# HDSC_HC32L110B4PA register map
Vendor: HDSC Co.Ltd; Series: ARMCM0P; File version: 1.2
CPU: CM0 r0p0, little endian, no MPU, no FPU, 3 interrupt priority bits
Registers are 32-bit, read-write, reset 0x0 unless marked. A register's access mark holds for its fields unless they carry their own. Offsets are from the block's base; [hi:lo] are bit positions; {n}, {i} and the like mark numbered series.

## BGR
Base 0x40002400; alternate view of ADC
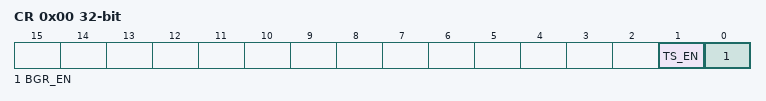
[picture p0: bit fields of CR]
0x00 CR
  [1] TS_EN, [0] BGR_EN

## BT0 — desc BT
Base 0x40000C00
Same registers: BT1 0x40000C20, BT2 0x40000C40
0x00 ARR (reset mask 0xFF)
  [15:0] ARR
0x04 CNT (reset mask 0xFF)
  [15:0] CNT
0x08 CNT32
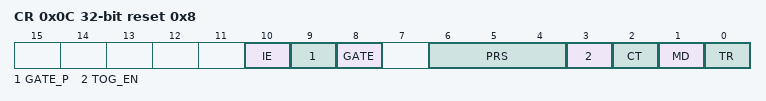
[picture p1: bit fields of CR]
0x0C CR reset 0x8
  [10] IE, [9] GATE_P, [8] GATE, [6:4] PRS, [3] TOG_EN, [2] CT, [1] MD, [0] TR
0x10 IFR ro
  [0] TF
0x14 ICLR wo reset 0x1
  [0] TFC

## CLK_TRIM
Base 0x40001800
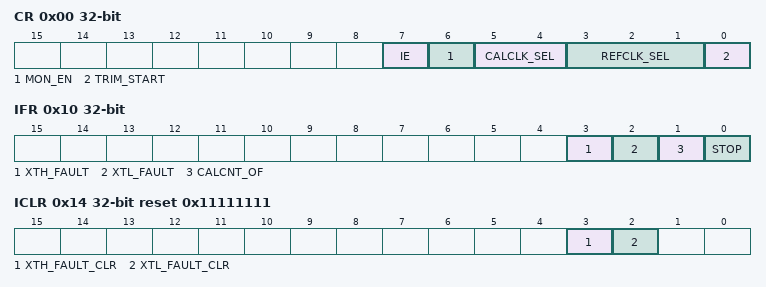
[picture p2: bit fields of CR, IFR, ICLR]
0x00 CR
  [7] IE, [6] MON_EN, [5:4] CALCLK_SEL, [3:1] REFCLK_SEL, [0] TRIM_START
0x04 REFCON
  [31:0] RCNTVAL
0x08 REFCNT ro
0x0C CALCNT ro
0x10 IFR ro
  [3] XTH_FAULT, [2] XTL_FAULT, [1] CALCNT_OF, [0] STOP
0x14 ICLR reset 0x11111111
  [3] XTH_FAULT_CLR, [2] XTL_FAULT_CLR
0x18 CALCON reset 0xFFFFFFFF
  [31:0] CCNTVAL

## CLOCK
Base 0x40002000
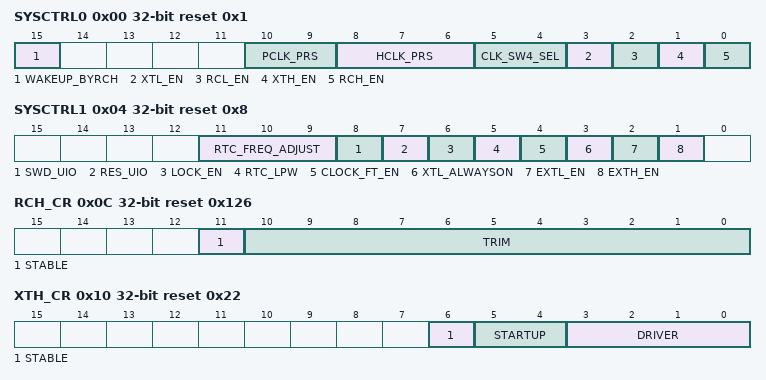
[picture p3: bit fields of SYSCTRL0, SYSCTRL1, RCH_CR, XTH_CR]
0x00 SYSCTRL0 reset 0x1
  [15] WAKEUP_BYRCH, [10:9] PCLK_PRS, [8:6] HCLK_PRS, [5:4] CLK_SW4_SEL, [3] XTL_EN, [2] RCL_EN, [1] XTH_EN, [0] RCH_EN
0x04 SYSCTRL1 reset 0x8
  [11:9] RTC_FREQ_ADJUST, [8] SWD_UIO, [7] RES_UIO, [6] LOCK_EN, [5] RTC_LPW, [4] CLOCK_FT_EN, [3] XTL_ALWAYSON, [2] EXTL_EN, [1] EXTH_EN
0x08 SYSCTRL2
  [15:0] SYSCTRL2
0x0C RCH_CR reset 0x126
  [11] STABLE ro, [10:0] TRIM
0x10 XTH_CR reset 0x22
  [6] STABLE ro, [5:4] STARTUP, [3:0] DRIVER
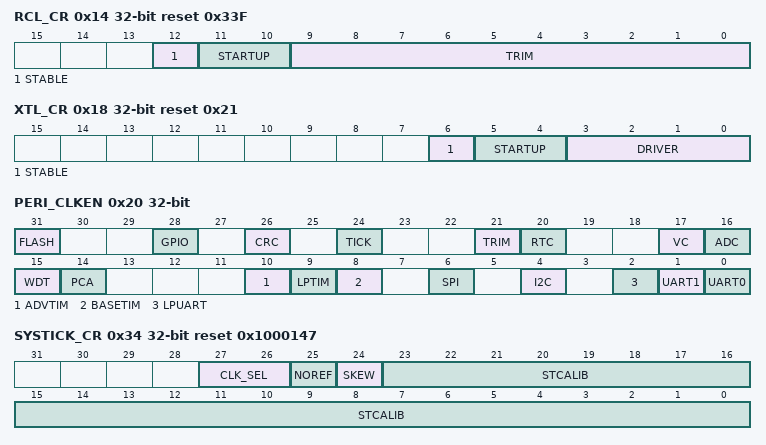
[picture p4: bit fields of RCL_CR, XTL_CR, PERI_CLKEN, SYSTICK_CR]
0x14 RCL_CR reset 0x33F
  [12] STABLE ro, [11:10] STARTUP, [9:0] TRIM
0x18 XTL_CR reset 0x21
  [6] STABLE ro, [5:4] STARTUP, [3:0] DRIVER
0x20 PERI_CLKEN
  [31] FLASH, [28] GPIO, [26] CRC, [24] TICK, [21] TRIM, [20] RTC, [17] VC, [16] ADC, [15] WDT, [14] PCA, [10] ADVTIM, [9] LPTIM, [8] BASETIM, [6] SPI, [4] I2C, [2] LPUART, [1] UART1, [0] UART0
0x34 SYSTICK_CR reset 0x1000147
  [27:26] CLK_SEL, [25] NOREF, [24] SKEW, [23:0] STCALIB
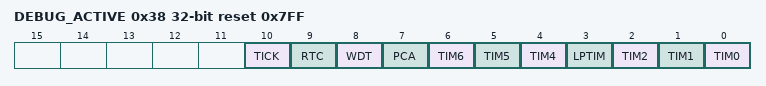
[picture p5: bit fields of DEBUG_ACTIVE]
0x38 DEBUG_ACTIVE reset 0x7FF
  [10] TICK, [9] RTC, [8] WDT, [7] PCA, [6] TIM6, [5] TIM5, [4] TIM4, [3] LPTIM, [2] TIM2, [1] TIM1, [0] TIM0

## CRC
Base 0x40020900
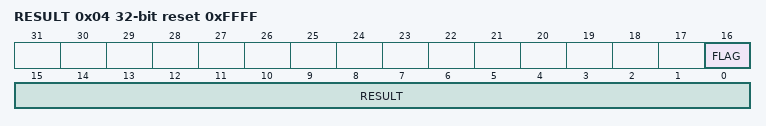
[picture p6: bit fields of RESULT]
0x04 RESULT reset 0xFFFF
  [16] FLAG ro, [15:0] RESULT
0x80 DATA wo

## FLASH
Base 0x40020000
0x00 TNVS reset 0x32
  [8:0] TNVS
0x04 TPGS reset 0x23
  [7:0] TPGS
0x08 TPROG reset 0x27
  [7:0] TPROG
0x0C TSERASE reset 0x18000
  [17:0] TSERASE
0x10 TMERASE reset 0x140000
  [20:0] TMERASE
0x14 TPRCV reset 0x24
  [11:0] TPRCV
0x18 TSRCV reset 0x240
  [11:0] TSRCV
0x1C TMRCV reset 0x1000
  [12:0] TMRCV
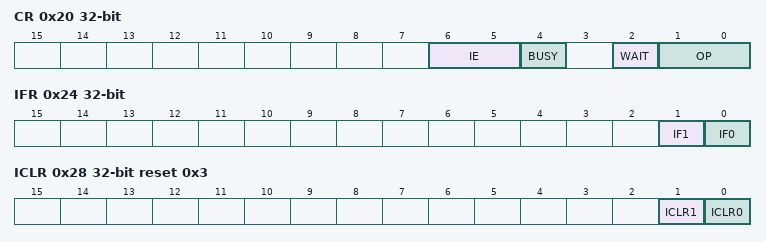
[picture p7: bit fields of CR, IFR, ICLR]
0x20 CR
  [6:5] IE, [4] BUSY ro, [2] WAIT, [1:0] OP
0x24 IFR ro
  [1] IF1, [0] IF0
0x28 ICLR wo reset 0x3
  [1] ICLR1, [0] ICLR0
0x2C BYPASS wo
  [15:0] BYSEQ
0x30 SLOCK
  [15:0] SLOCK

## GPIO
Base 0x40020C00
0x04 P01_SEL
  [2:0] SEL
0x08 P02_SEL
  [2:0] SEL
0x50 P14_SEL
  [2:0] SEL
0x54 P15_SEL
  [2:0] SEL
{0x30+4i} P{i}_SEL (i=23..27)
  [2:0] SEL
0xC4 P31_SEL
  [2:0] SEL
0xD4 P35_SEL
  [2:0] SEL
0xD8 P36_SEL
  [2:0] SEL
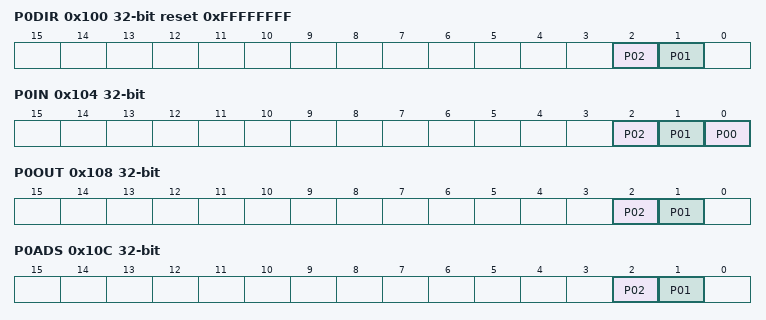
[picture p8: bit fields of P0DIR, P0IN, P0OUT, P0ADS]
0x100 P0DIR reset 0xFFFFFFFF
  [2] P02, [1] P01
0x104 P0IN ro
  [2] P02, [1] P01, [0] P00
0x108 P0OUT
  [2] P02, [1] P01
0x10C P0ADS
  [2] P02, [1] P01
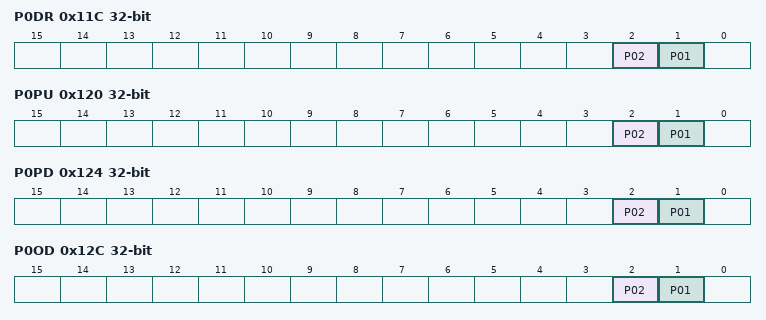
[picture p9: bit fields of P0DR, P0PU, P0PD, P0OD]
0x11C P0DR
  [2] P02, [1] P01
0x120 P0PU
  [2] P02, [1] P01
0x124 P0PD
  [2] P02, [1] P01
0x12C P0OD
  [2] P02, [1] P01
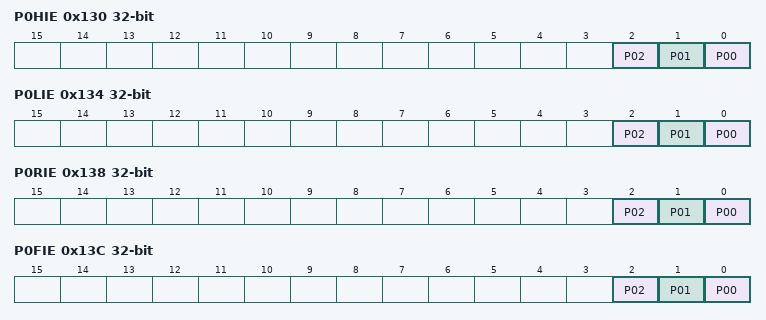
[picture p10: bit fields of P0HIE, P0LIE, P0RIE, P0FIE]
0x130 P0HIE ro
  [2] P02, [1] P01, [0] P00
0x134 P0LIE ro
  [2] P02, [1] P01, [0] P00
0x138 P0RIE ro
  [2] P02, [1] P01, [0] P00
0x13C P0FIE ro
  [2] P02, [1] P01, [0] P00
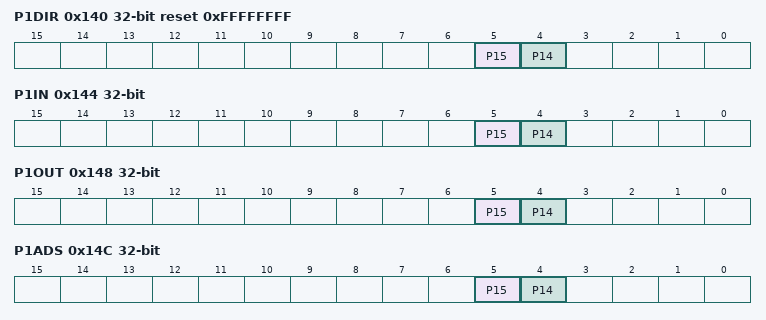
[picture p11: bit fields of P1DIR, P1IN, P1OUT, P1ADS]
0x140 P1DIR reset 0xFFFFFFFF
  [5] P15, [4] P14
0x144 P1IN ro (reset mask 0x3)
  [5] P15, [4] P14
0x148 P1OUT
  [5] P15, [4] P14
0x14C P1ADS
  [5] P15, [4] P14
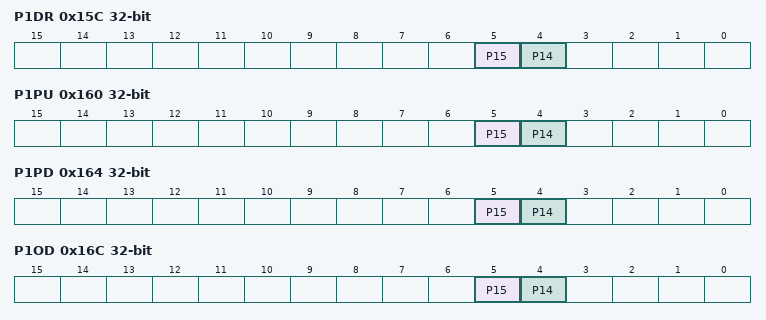
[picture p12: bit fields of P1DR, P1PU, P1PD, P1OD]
0x15C P1DR
  [5] P15, [4] P14
0x160 P1PU
  [5] P15, [4] P14
0x164 P1PD
  [5] P15, [4] P14
0x16C P1OD
  [5] P15, [4] P14
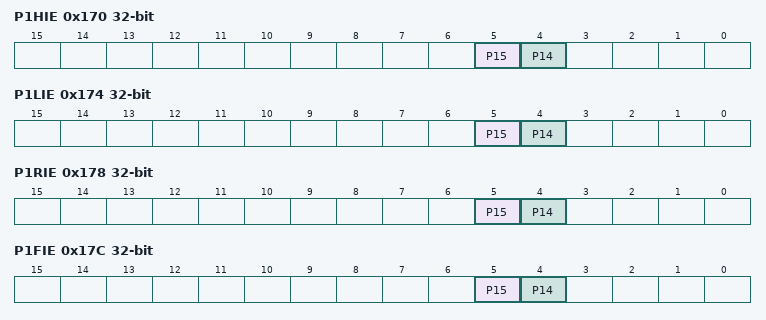
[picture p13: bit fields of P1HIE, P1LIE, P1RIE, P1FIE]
0x170 P1HIE ro (reset mask 0x3)
  [5] P15, [4] P14
0x174 P1LIE ro (reset mask 0x3)
  [5] P15, [4] P14
0x178 P1RIE ro (reset mask 0x3)
  [5] P15, [4] P14
0x17C P1FIE ro (reset mask 0x3)
  [5] P15, [4] P14
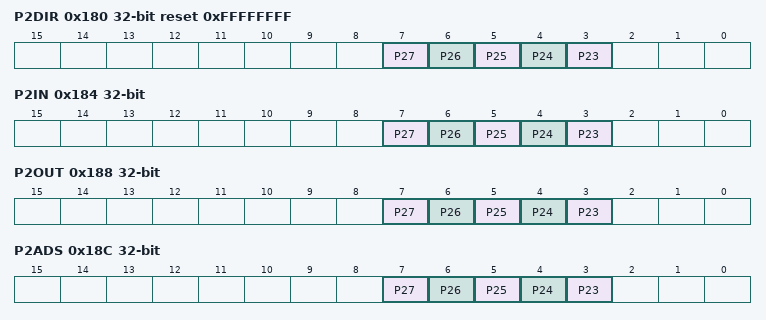
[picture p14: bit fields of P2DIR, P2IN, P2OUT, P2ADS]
0x180 P2DIR reset 0xFFFFFFFF
  [n-20] P{n} (n=23..27)
0x184 P2IN ro (reset mask 0x3)
  [n-20] P{n} (n=23..27)
0x188 P2OUT
  [n-20] P{n} (n=23..27)
0x18C P2ADS
  [n-20] P{n} (n=23..27)
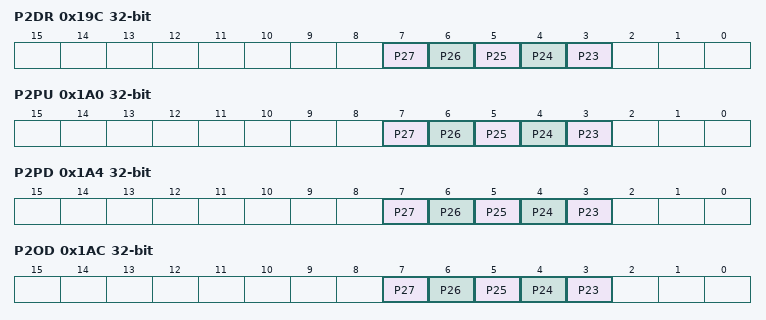
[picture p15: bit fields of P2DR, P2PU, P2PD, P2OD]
0x19C P2DR
  [n-20] P{n} (n=23..27)
0x1A0 P2PU
  [n-20] P{n} (n=23..27)
0x1A4 P2PD
  [n-20] P{n} (n=23..27)
0x1AC P2OD
  [n-20] P{n} (n=23..27)
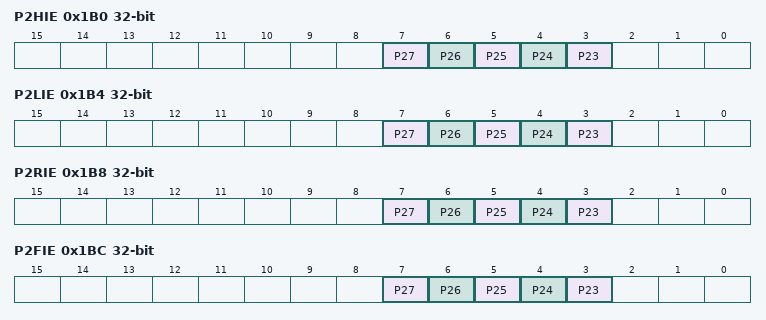
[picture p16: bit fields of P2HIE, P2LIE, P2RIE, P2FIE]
0x1B0 P2HIE ro (reset mask 0x3)
  [n-20] P{n} (n=23..27)
0x1B4 P2LIE ro (reset mask 0x3)
  [n-20] P{n} (n=23..27)
0x1B8 P2RIE ro (reset mask 0x3)
  [n-20] P{n} (n=23..27)
0x1BC P2FIE ro (reset mask 0x3)
  [n-20] P{n} (n=23..27)
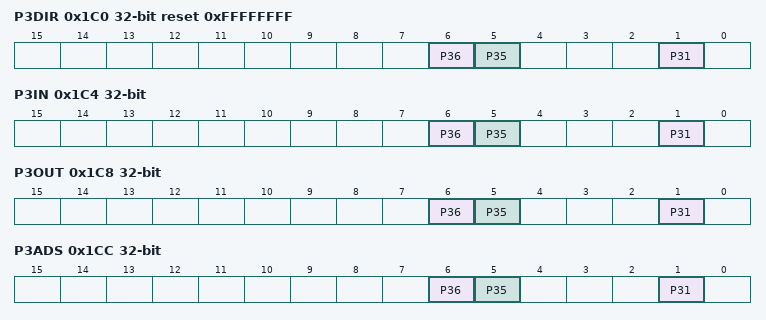
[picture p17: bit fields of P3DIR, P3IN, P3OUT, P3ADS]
0x1C0 P3DIR reset 0xFFFFFFFF
  [6] P36, [5] P35, [1] P31
0x1C4 P3IN ro
  [6] P36, [5] P35, [1] P31
0x1C8 P3OUT
  [6] P36, [5] P35, [1] P31
0x1CC P3ADS
  [6] P36, [5] P35, [1] P31
0x1DC P3DR
  [6] P36, [5] P35, [1] P31
0x1E0 P3PU
  [6] P36, [5] P35, [1] P31
0x1E4 P3PD
  [6] P36, [5] P35, [1] P31
0x1EC P3OD
  [6] P36, [5] P35, [1] P31
0x1F0 P3HIE ro
  [6] P36, [5] P35, [1] P31
0x1F4 P3LIE ro
  [6] P36, [5] P35, [1] P31
0x1F8 P3RIE ro
  [6] P36, [5] P35, [1] P31
0x1FC P3FIE ro
  [6] P36, [5] P35, [1] P31
0x200 P0STAT ro
  [2] P02, [1] P01, [0] P00
0x210 P0ICLR ro
  [2] P02, [1] P01, [0] P00
0x240 P1STAT ro (reset mask 0x3)
  [5] P15, [4] P14
0x250 P1ICLR ro (reset mask 0x3)
  [5] P15, [4] P14
0x280 P2STAT ro (reset mask 0x3)
  [n-20] P{n} (n=23..27)
0x290 P2ICLR ro (reset mask 0x3)
  [n-20] P{n} (n=23..27)
0x2C0 P3STAT ro
  [6] P36, [5] P35, [1] P31
0x2D0 P3ICLR ro
  [6] P36, [5] P35, [1] P31
0x300 CTRL0 reset 0x1
  [0] IESEL
0x304 CTRL1
  [14] IR_POL, [13] HCLK_EN, [12] PCLK_EN, [11:10] HCLK_SEL, [9:8] PCLK_SEL, [7:4] SSN_SEL, [3:0] EXT_CLK_SEL
0x308 CTRL2
  [2n+1:2n] PCA_CAP{n}_SEL (n=0..4)
0x30C CTRL3
  [11:10] TM6_A_SEL, [9:8] TM5_A_SEL, [7:6] TM4_A_SEL, [5:4] TM6_B_SEL, [3:2] TM5_B_SEL, [1:0] TM4_B_SEL
0x310 CTRL4
  [2n+1:2n] TM{n}_GATE_SEL (n=0..3)
